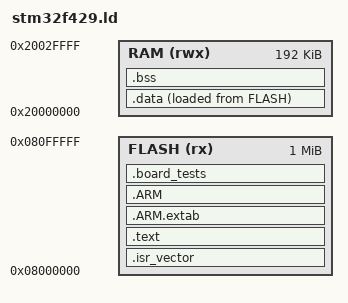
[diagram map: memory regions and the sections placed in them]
ENTRY(Reset_Handler)

MEMORY
{
    FLASH (rx)  : ORIGIN = 0x08000000, LENGTH = 1024K
    RAM   (rwx) : ORIGIN = 0x20000000, LENGTH = 192K
}

_estack = ORIGIN(RAM) + LENGTH(RAM);

SECTIONS
{
    .isr_vector :
    {
        . = ALIGN(2048);
        KEEP(*(.isr_vector))
        . = ALIGN(4);
    } > FLASH

    .text :
    {
        . = ALIGN(4);
        *(.text*)
        *(.rodata*)
        . = ALIGN(4);
    } > FLASH

    .ARM.extab :
    {
        *(.ARM.extab* .gnu.linkonce.armextab.*)
    } > FLASH

    .ARM :
    {
        __exidx_start = .;
        *(.ARM.exidx*)
        __exidx_end = .;
    } > FLASH

    .board_tests :
    {
        . = ALIGN(4);
        __board_tests_start = .;
        KEEP(*(BOARD_TESTS))
        __board_tests_end = .;
        . = ALIGN(4);
    } > FLASH

    _sidata = LOADADDR(.data);

    .data :
    {
        . = ALIGN(4);
        _sdata = .;
        *(.data*)
        . = ALIGN(4);
        _edata = .;
    } > RAM AT> FLASH

    .bss :
    {
        . = ALIGN(4);
        _sbss = .;
        *(.bss*)
        *(COMMON)
        . = ALIGN(4);
        _ebss = .;
    } > RAM

    end = .;
    _end = .;
}
